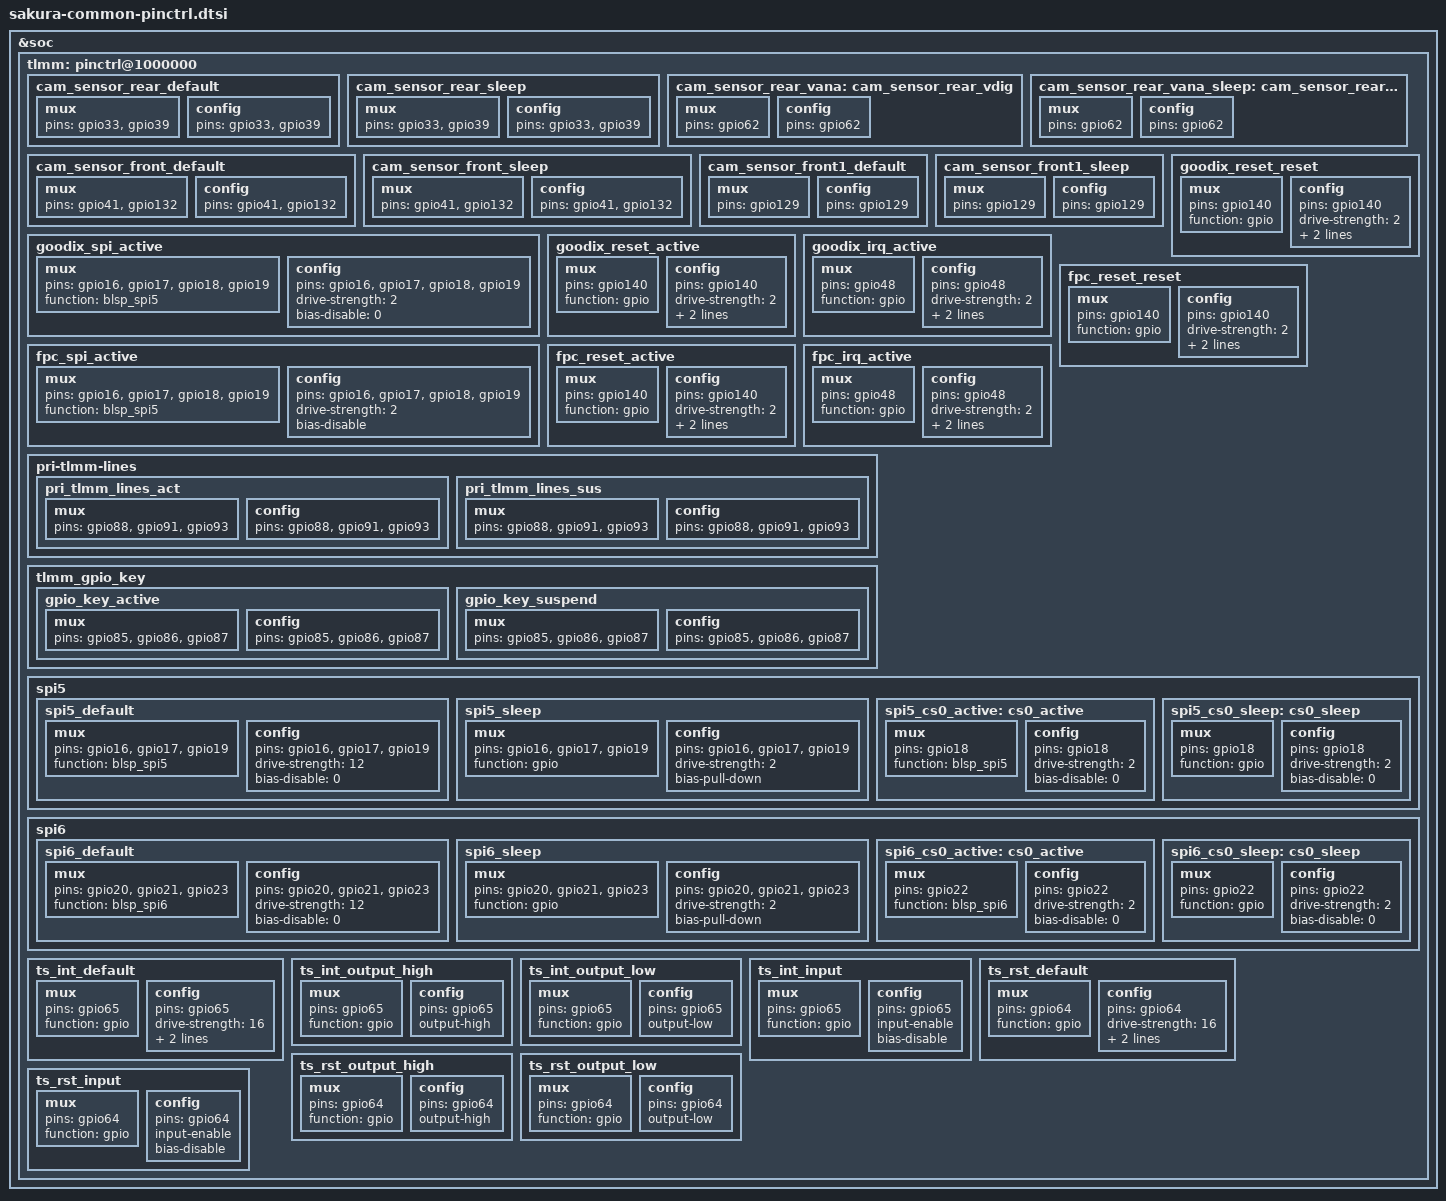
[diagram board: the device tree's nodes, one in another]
/* msm8953-pinctrl */

&tlmm {
    spi5 {
        spi5_default: spi5_default {
            /* active state */
            mux {
                /* MOSI, MISO, CLK */
                pins = "gpio16", "gpio17", "gpio19";
                function = "blsp_spi5";
            };

            config {
                pins = "gpio16", "gpio17", "gpio19";
                drive-strength = <12>; /* 12 MA */
                bias-disable = <0>; /* No PULL */
            };
        };

        spi5_sleep: spi5_sleep {
            /* suspended state */
            mux {
                /* MOSI, MISO, CLK */
                pins = "gpio16", "gpio17", "gpio19";
                function = "gpio";
            };

            config {
                pins = "gpio16", "gpio17", "gpio19";
                drive-strength = <2>; /* 2 MA */
                bias-pull-down; /* PULL Down */
            };
        };

        spi5_cs0_active: cs0_active {
            /* CS */
            mux {
                pins = "gpio18";
                function = "blsp_spi5";
            };

            config {
                pins = "gpio18";
                drive-strength = <2>;
                bias-disable = <0>;
            };
        };

        spi5_cs0_sleep: cs0_sleep {
            /* CS */
            mux {
                pins = "gpio18";
                function = "gpio";
            };

            config {
                pins = "gpio18";
                drive-strength = <2>;
                bias-disable = <0>;
            };
        };
	};

	spi6 {
		spi6_default: spi6_default {
			/* active state */
			mux {
				/* MOSI, MISO, CLK */
				pins = "gpio20", "gpio21", "gpio23";
				function = "blsp_spi6";
			};

			config {
				pins = "gpio20", "gpio21", "gpio23";
				drive-strength = <12>; /* 12 MA */
				bias-disable = <0>; /* No PULL */
			};
		};

		spi6_sleep: spi6_sleep {
			/* suspended state */
			mux {
				/* MOSI, MISO, CLK */
				pins = "gpio20", "gpio21", "gpio23";
				function = "gpio";
			};

			config {
				pins = "gpio20", "gpio21", "gpio23";
				drive-strength = <2>; /* 2 MA */
				bias-pull-down; /* PULL Down */
			};
		};

		spi6_cs0_active: cs0_active {
			/* CS */
			mux {
				pins = "gpio22";
				function = "blsp_spi6";
			};

			config {
				pins = "gpio22";
				drive-strength = <2>;
				bias-disable = <0>;
			};
		};

		spi6_cs0_sleep: cs0_sleep {
			/* CS */
			mux {
				pins = "gpio22";
				function = "gpio";
			};

			config {
				pins = "gpio22";
				drive-strength = <2>;
				bias-disable = <0>;
			};
		};
	};
};

&soc {
	tlmm: pinctrl@1000000 {
		cam_sensor_rear_default: cam_sensor_rear_default {
			mux {
				pins = "gpio33", "gpio39";
			};
			config {
				pins = "gpio33", "gpio39";
			};
		};
		cam_sensor_rear_sleep: cam_sensor_rear_sleep {
			mux {
				pins = "gpio33", "gpio39";
			};
			config {
				pins = "gpio33", "gpio39";
			};
		};
		cam_sensor_rear_vana: cam_sensor_rear_vdig {
			mux {
				pins = "gpio62";
			};
			config {
				pins = "gpio62";
			};
		};
		cam_sensor_rear_vana_sleep: cam_sensor_rear_vdig_sleep {
			mux {
				pins = "gpio62";
			};
			config {
				pins = "gpio62";
			};
		};
		cam_sensor_front_default: cam_sensor_front_default {
			mux {
				pins = "gpio41","gpio132";
			};
			config {
				pins = "gpio41","gpio132";
			};
		};
		cam_sensor_front_sleep: cam_sensor_front_sleep {
			mux {
				pins = "gpio41","gpio132";
			};
			config {
				pins = "gpio41","gpio132";
			};
		};
		cam_sensor_front1_default: cam_sensor_front1_default {
			mux {
				pins = "gpio129";
			};
			config {
				pins = "gpio129";
			};
		};
		cam_sensor_front1_sleep: cam_sensor_front1_sleep {
			mux {
				pins = "gpio129";
			};
			config {
				pins = "gpio129";
			};
		};
		/*fp gpio of goodix & fpc */
		goodix_spi_active: goodix_spi_active{
			mux {
				pins = "gpio16", "gpio17", "gpio18", "gpio19";
				function = "blsp_spi5";
			};
			config {
				pins = "gpio16", "gpio17", "gpio18", "gpio19";
				drive-strength = <2>;
				bias-disable = <0>;
			};
		};
		goodix_reset_reset: goodix_reset_reset{
			mux {
				pins = "gpio140";
				function = "gpio";
			};
			config {
				pins = "gpio140";
				drive-strength = <2>;
				bias-disable = <0>;
				output-low;
			};
		};
		goodix_reset_active: goodix_reset_active{
			mux {
				pins = "gpio140";
				function = "gpio";
			};
			config {
				pins = "gpio140";
				drive-strength = <2>;
				bias-disable = <0>;
				output-high;
			};
		};
		goodix_irq_active: goodix_irq_active {
			mux {
				pins = "gpio48";
				function = "gpio";
			};
			config {
				pins = "gpio48";
				drive-strength = <2>;
				bias-disable = <0>;
				input-enable;
			};
		};

		/* fingerprint pin function */
		fpc_spi_active: fpc_spi_active {
			mux {
				pins = "gpio16", "gpio17", "gpio18", "gpio19";
				function = "blsp_spi5";
			};

			config {
				pins = "gpio16", "gpio17", "gpio18", "gpio19";
				drive-strength = <2>;
				bias-disable;
			};
		};
		fpc_reset_reset: fpc_reset_reset {
			mux {
				pins = "gpio140";
				function = "gpio";
			};
			config {
				pins = "gpio140";
				drive-strength = <2>;
				bias-disable;
				output-low;
			};
		};
		fpc_reset_active: fpc_reset_active {
			mux {
				pins = "gpio140";
				function = "gpio";
			};
			config {
				pins = "gpio140";
				drive-strength = <2>;
				bias-disable;
				output-high;
			};
		};
		fpc_irq_active: fpc_irq_active {
			mux {
				pins = "gpio48";
				function = "gpio";
			};
			config {
				pins = "gpio48";
				drive-strength = <2>;
				bias-disable;
				input-enable;
			};
		};
		pri-tlmm-lines {
			pri_tlmm_lines_act: pri_tlmm_lines_act {
				mux {
					pins = "gpio88", "gpio91", "gpio93";
				};
				config {
					pins = "gpio88", "gpio91", "gpio93";
				};
			};
			pri_tlmm_lines_sus: pri_tlmm_lines_sus {
				mux {
					pins = "gpio88", "gpio91", "gpio93";
				};
				config {
					pins = "gpio88", "gpio91", "gpio93";
				};
			};
		};

		tlmm_gpio_key {
			gpio_key_active: gpio_key_active {
				mux {
					pins = "gpio85", "gpio86", "gpio87";
				};
				config {
					pins = "gpio85", "gpio86", "gpio87";
				};
			};
			gpio_key_suspend: gpio_key_suspend {
				mux {
					pins = "gpio85", "gpio86", "gpio87";
				};
				config {
					pins = "gpio85", "gpio86", "gpio87";
				};
			};
		};
	};
};

&tlmm {
	/* add pingrp for goodix touch */
	ts_int_default: ts_int_default {
		mux {
			pins = "gpio65";
			function = "gpio";
		};
		config {
			pins = "gpio65";
			drive-strength = <16>;
			/*bias-pull-up;*/
			input-enable;
			bias-disable;
		};
	};

	ts_int_output_high: ts_int_output_high {
		mux {
			pins = "gpio65";
			function = "gpio";
		};
		config {
			pins = "gpio65";
			output-high;
		};
	};

	ts_int_output_low: ts_int_output_low {
		mux {
			pins = "gpio65";
			function = "gpio";
		};
		config {
			pins = "gpio65";
			output-low;
		};
	};

	ts_int_input: ts_int_input {
		mux {
			pins = "gpio65";
			function = "gpio";
		};
		config {
			pins = "gpio65";
			input-enable;
			bias-disable;
		};
	};

	ts_rst_default: ts_rst_default {
		mux {
			pins = "gpio64";
			function = "gpio";
		};
		config {
			pins = "gpio64";
			drive-strength = <16>;
			/*bias-pull-up;*/
			input-enable;
			bias-disable;
		};
	};

	ts_rst_output_high: ts_rst_output_high {
		mux {
			pins = "gpio64";
			function = "gpio";
		};
		config {
			pins = "gpio64";
			output-high;
		};
	};

	ts_rst_output_low: ts_rst_output_low {
		mux {
			pins = "gpio64";
			function = "gpio";
		};
		config {
			pins = "gpio64";
			output-low;
		};
	};

	ts_rst_input: ts_rst_input {
		mux {
			pins = "gpio64";
			function = "gpio";
		};
		config {
			pins = "gpio64";
			input-enable;
			bias-disable;
		};
	};
};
